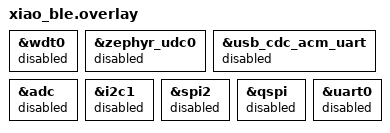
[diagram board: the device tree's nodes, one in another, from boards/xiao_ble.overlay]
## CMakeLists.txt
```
# Standalone Zephyr build for the fw1 -> fw2 (Option B) migrator.
#
# Built for the xiao_ble board to produce the unsigned base image. The ESPHome
# nrf52 build invokes this automatically (west build) during a migrator firmware
# compile, then patches the embedded fw2-bootloader blob into the result and
# signs it (see ../xiao_ble_mcuboot_migrator.py.script and README.md). No
# prebuilt binary is committed.

cmake_minimum_required(VERSION 3.20.0)

find_package(Zephyr REQUIRED HINTS $ENV{ZEPHYR_BASE})
project(xiao_ble_mcuboot_migrator LANGUAGES C)

target_sources(app PRIVATE
  src/main.c
  src/migrate.c
  src/blob.c
)

target_include_directories(app PRIVATE src)
```

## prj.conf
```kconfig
# fw1 -> fw2 (Option B) migrator -- standalone Zephyr app.
#
# This app is built ONCE, offline, into a prebuilt base binary (see README.md);
# the ESPHome build only patches the embedded fw2-bootloader blob into it. Keep
# it tiny and self-contained -- it must fit fw1's single application slot
# (0x78000) with the 48 KiB blob, and its critical section runs from RAM with
# IRQs off.

# No console/logging/printk: smaller image, no UART dependency.
CONFIG_CONSOLE=n
CONFIG_UART_CONSOLE=n
CONFIG_LOG=n
CONFIG_PRINTK=n
CONFIG_BOOT_BANNER=n
CONFIG_SERIAL=n

# CRITICAL (BOOTLOADER_UPDATER_PLAN.md 6.3): never start the watchdog. The
# nRF52 WDT cannot be stopped once running and the RAM critical section runs
# for many seconds with IRQs disabled, so it must not exist to expire.
CONFIG_WATCHDOG=n

# The critical erase/program/UICR routine executes from RAM (__ramfunc) because
# it erases the flash it was loaded from. ARCH_HAS_RAMFUNC_SUPPORT is a
# promptless symbol auto-selected by the Cortex-M arch -- it must NOT be assigned
# here (NCS Kconfig errors out when a selected/promptless symbol is assigned).

# CRC for blob integrity checking before the critical section.
CONFIG_CRC=y

# No USB stack: the migrator needs no host interaction; it runs and resets.
CONFIG_USB_DEVICE_STACK=n

# Headered for fw1's single-slot MCUboot (hash-only, signature type none -- see
# BOOTLOADER_UPDATER_PLAN.md 5). The image-signing step still needs a key file
# even though the bootloader does not verify it.
CONFIG_BOOTLOADER_MCUBOOT=y
CONFIG_MCUBOOT_SIGNATURE_KEY_FILE="root-ec-p256.pem"

# Keep the toolchain/libc minimal.
CONFIG_NFCT_PINS_AS_GPIOS=y
CONFIG_GPIO=n
CONFIG_REBOOT=y
```

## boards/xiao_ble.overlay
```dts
/*
 * Migrator board overlay (xiao_ble). Trims the device tree to the bare minimum:
 * the migrator only touches NVMC/UICR registers directly and resets. Disabling
 * the watchdog node reinforces prj.conf's CONFIG_WATCHDOG=n
 * (BOOTLOADER_UPDATER_PLAN.md 6.3 -- the WDT must never start).
 */

&wdt0 {
	status = "disabled";
};

&zephyr_udc0 {
	status = "disabled";
};

&usb_cdc_acm_uart {
	status = "disabled";
};

&adc {
	status = "disabled";
};

&i2c1 {
	status = "disabled";
};

&spi2 {
	status = "disabled";
};

&qspi {
	status = "disabled";
};

&uart0 {
	status = "disabled";
};
```

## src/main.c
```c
/*
 * fw1 -> fw2 (Option B) migrator entry point.
 *
 * Runs once, from fw1's single application slot. It validates the embedded
 * fw2-bootloader blob entirely from flash (safe: nothing is erased yet), copies
 * it into RAM, then hands off to the RAM-resident critical section that
 * actually rewrites flash and retargets UICR. See migrate.c for the dangerous
 * part and BOOTLOADER_UPDATER_PLAN.md for the design.
 *
 * Built with the watchdog disabled (BOOTLOADER_UPDATER_PLAN.md section 6.3):
 * the nRF52 WDT cannot be stopped once started, and the critical section runs
 * for many seconds with IRQs off, so it must never be fed/expired.
 */

#include <string.h>

#include <zephyr/kernel.h>
#include <zephyr/sys/crc.h>

#include "migrator.h"

/* RAM-resident copy of the blob (.bss). The critical section erases the flash
 * the original lives in, so it can only read this RAM copy. */
static struct mig_blob ram_blob;

/* Validation failed before anything was written: nothing is erased, so fw1 is
 * untouched. Stay parked (re-upload a fixed migrator over fw1 serial recovery)
 * rather than risk a half-baked migration. */
static void mig_park(void) {
  while (1) {
    k_msleep(1000);
  }
}

static int mig_blob_valid(const struct mig_blob *blob) {
  if (memcmp(blob->magic, MIG_BLOB_MAGIC, MIG_BLOB_MAGIC_LEN) != 0) {
    return 0;
  }
  if (blob->format_version != MIG_BLOB_FORMAT_VERSION) {
    return 0;
  }
  if (blob->blob_len == 0u || blob->blob_len > MIG_BLOB_CAPACITY) {
    return 0;
  }
  if (blob->target_addr != MIG_FW2_BOOTLOADER_ADDR) {
    return 0;
  }
  return crc32_ieee(blob->data, blob->blob_len) == blob->blob_crc32;
}

int main(void) {
  /* Let power/USB settle and give a human a beat to spot that the migrator
   * booted before the long, headless critical section begins. */
  k_msleep(500);

  if (!mig_blob_valid(&mig_embedded_blob)) {
    mig_park();
  }

  memcpy(&ram_blob, &mig_embedded_blob, sizeof(ram_blob));

  /* Re-validate the RAM copy: a bad memcpy/RAM fault must not reach flash. */
  if (!mig_blob_valid(&ram_blob)) {
    mig_park();
  }

  /* Hands off to RAM. Returns only on a pre-commit failure (fw1 still boots). */
  mig_run_from_ram(&ram_blob);

  mig_park();
  return 0;
}
```

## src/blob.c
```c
/*
 * Placeholder for the embedded fw2-bootloader blob.
 *
 * This object reserves space and a locatable magic marker; it carries no real
 * bootloader bytes. The ESPHome build-time injector
 * (xiao_ble_mcuboot_migrator.py.script) finds MIG_BLOB_MAGIC in the compiled
 * .bin and overwrites blob_len / blob_crc32 / target_addr / data[] with the
 * actual relocated fw2 MCUboot extracted from that build's merged.hex.
 *
 * It lives in .rodata (a non-zero initializer keeps it in the loadable image
 * rather than .bss) and is referenced by main(), so it is emitted verbatim
 * into the .bin and the injector can find it by scanning for MIG_BLOB_MAGIC.
 */

#include "migrator.h"

#ifdef __ZEPHYR__
#include <zephyr/toolchain.h>
#include <zephyr/sys/util.h>
#endif

#include <stddef.h>

/* The header must stay a fixed 32 bytes so the injector can patch by offset. */
#ifdef BUILD_ASSERT
BUILD_ASSERT(offsetof(struct mig_blob, data) == 32,
             "mig_blob header must be exactly 32 bytes");
BUILD_ASSERT(MIG_BLOB_CAPACITY >= MIG_FW2_BOOTLOADER_SIZE,
             "blob capacity too small for the fw2 bootloader region");
#endif

/* data[] must be non-zero so the whole object stays in the loadable image; the
 * 0xFF fill also matches erased flash, which the injector pads short blobs with
 * (GCC range designator -- the migrator is GCC-only under Zephyr). */
const struct mig_blob mig_embedded_blob __attribute__((used)) = {
    .magic = MIG_BLOB_MAGIC,
    .blob_len = 0u,             /* patched by the injector */
    .blob_crc32 = 0u,           /* patched by the injector */
    .target_addr = 0xFFFFFFFFu, /* patched by the injector */
    .format_version = MIG_BLOB_FORMAT_VERSION,
    .data = {[0 ... MIG_BLOB_CAPACITY - 1] = 0xFF},
};
```

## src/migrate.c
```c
/*
 * Option B critical section: program the relocated fw2 MCUboot and retarget
 * UICR.NRFFW[0], all from RAM with IRQs disabled.
 *
 * This routine erases and reprograms the very flash region the migrator was
 * loaded into (fw1's app slot starts at 0x1000, which is also the fw2
 * bootloader address), so it -- and the blob it programs -- must already live
 * in RAM before the first erase. main() copies the blob to RAM and marks this
 * code __ramfunc so Zephyr relocates it at boot.
 *
 * Ordering is chosen so fw1 stays bootable until the last possible instant:
 *   1. erase fw2 regions (BL + both slots + settings); MBR @0x0 and fw1 BL
 *      @0xF4000 are NOT in the window, so UICR.NRFFW[0] still forwards to fw1.
 *   2. program the relocated fw2 MCUboot; verify its vector table.
 *   3. on a bad vector table, just reset -- fw1 (via the untouched MBR/UICR)
 *      still comes up in serial recovery. No commit happened.
 *   4. only after the vector table checks out: ERASEUICR, then rewrite
 *      NRFFW[0]/NRFFW[1] + NFC-pins-as-GPIO + REGOUT0. This single commit flips
 *      the boot path from fw1 to fw2.
 *   5. reset into fw2 (empty primary slot -> recovery).
 *
 * See BOOTLOADER_UPDATER_PLAN.md sections 4-6 and migrator_layout.h.
 */

#include "migrator.h"

#include <nrf.h>
/*
 * Pulls in Zephyr's real __ramfunc (toolchain/gcc.h): when
 * CONFIG_ARCH_HAS_RAMFUNC_SUPPORT=y it places functions in the .ramfunc section
 * that the startup copies into RAM. Without this include, __ramfunc was
 * undefined here and the local empty fallback below left the entire critical
 * section in flash -- so the first erase wiped the page it was executing from
 * and the migration faulted partway (slot erased, UICR never committed).
 */
#include <zephyr/kernel.h>

/* NFCPINS.PROTECT cleared -> P0.09/P0.10 usable as GPIO (matches the fw2 app's
 * nfct-pins-as-gpios). After ERASEUICR the field reads 0xFFFFFFFF (NFC mode),
 * so the migrator must re-apply this. REGOUT0 (3.0V) is rewritten in the same
 * commit -- see MIG_UICR_REGOUT0_* in migrator_layout.h: the board will not run
 * fw2 at the erased 1.8V default, so it cannot be left to the fw2 app. */
#define MIG_UICR_NFCPINS_GPIO 0xFFFFFFFEu

/*
 * The critical section MUST run from RAM (it erases its own flash). Never define
 * __ramfunc to nothing as a fallback: a no-op silently produces flash-resident
 * critical code that self-erases mid-run and bricks the migration. If the arch
 * cannot relocate to RAM, fail the build loudly instead.
 */
#if !defined(CONFIG_ARCH_HAS_RAMFUNC_SUPPORT)
#error "migrator requires CONFIG_ARCH_HAS_RAMFUNC_SUPPORT: the critical erase/program section must execute from RAM"
#endif

static __ramfunc void mig_nvmc_wait(void) {
  while (NRF_NVMC->READY == NVMC_READY_READY_Busy) {
  }
}

static __ramfunc void mig_nvmc_config(uint32_t mode) {
  NRF_NVMC->CONFIG = mode;
  __DSB();
  mig_nvmc_wait();
}

static __ramfunc void mig_erase_range(uint32_t start, uint32_t end) {
  mig_nvmc_config(NVMC_CONFIG_WEN_Een);
  for (uint32_t page = start; page < end; page += MIG_FLASH_PAGE_SIZE) {
    NRF_NVMC->ERASEPAGE = page;
    __DSB();
    mig_nvmc_wait();
  }
  mig_nvmc_config(NVMC_CONFIG_WEN_Ren);
}

static __ramfunc void mig_program(uint32_t addr, const uint8_t *data, uint32_t len) {
  volatile uint32_t *dst = (volatile uint32_t *) addr;
  mig_nvmc_config(NVMC_CONFIG_WEN_Wen);
  for (uint32_t offset = 0; offset < len; offset += 4) {
    uint32_t word = 0xFFFFFFFFu;
    /* Little-endian assembly that tolerates a non-word-multiple tail. */
    uint8_t *wb = (uint8_t *) &word;
    for (uint32_t b = 0; b < 4 && (offset + b) < len; b++) {
      wb[b] = data[offset + b];
    }
    *dst = word;
    __DSB();
    mig_nvmc_wait();
    dst++;
  }
  mig_nvmc_config(NVMC_CONFIG_WEN_Ren);
}

/*
 * Reset from RAM. NVIC_SystemReset() is reached through a flash veneer
 * (____NVIC_SystemReset_veneer: `ldr pc,[pc]`) that lives in the region this
 * routine just erased -- jumping there faults. Inline the AIRCR write in a
 * __ramfunc so the reset never touches flash.
 */
static __ramfunc void mig_reset(void) {
  __DSB();
  SCB->AIRCR =
      (uint32_t) ((0x5FAUL << SCB_AIRCR_VECTKEY_Pos) | (SCB->AIRCR & SCB_AIRCR_PRIGROUP_Msk) | SCB_AIRCR_SYSRESETREQ_Msk);
  __DSB();
  for (;;) {
  }
}

static __ramfunc void mig_uicr_write(uint32_t addr, uint32_t value) {
  mig_nvmc_config(NVMC_CONFIG_WEN_Wen);
  *(volatile uint32_t *) addr = value;
  __DSB();
  mig_nvmc_wait();
  mig_nvmc_config(NVMC_CONFIG_WEN_Ren);
}

static __ramfunc void mig_uicr_erase(void) {
  mig_nvmc_config(NVMC_CONFIG_WEN_Een);
  NRF_NVMC->ERASEUICR = NVMC_ERASEUICR_ERASEUICR_Erase;
  __DSB();
  mig_nvmc_wait();
  mig_nvmc_config(NVMC_CONFIG_WEN_Ren);
}

/* A valid Cortex-M vector table starts with the initial stack pointer (must
 * point into RAM) followed by the reset vector (a thumb address in flash). */
static __ramfunc int mig_vector_table_ok(uint32_t addr) {
  const uint32_t *vt = (const uint32_t *) addr;
  uint32_t sp = vt[0];
  uint32_t reset = vt[1];
  if (sp < MIG_RAM_START || sp > MIG_RAM_END) {
    return 0;
  }
  if ((reset & 1u) == 0u) { /* reset vector must be a thumb (odd) address */
    return 0;
  }
  if (reset < MIG_ERASE_START || reset >= MIG_FLASH_END) {
    return 0;
  }
  return 1;
}

void __ramfunc mig_run_from_ram(const struct mig_blob *blob) {
  __disable_irq();

  /* Disable the ARM MPU and the NVMC instruction cache before touching flash.
   * Programming nRF flash is a CPU store straight to the flash address; if the
   * MPU's code-region attributes forbid that store in our context it faults, and
   * because we run from RAM with our own vector table about to be erased, that
   * fault escalates to an unrecoverable lockup. Disabling the MPU here keeps the
   * direct flash stores legal; clearing ICACHE keeps post-write readbacks
   * (mig_vector_table_ok) coherent with what we just programmed. Both are safe:
   * IRQs are off and we execute entirely from RAM. */
  MPU->CTRL = 0u;
  __DSB();
  __ISB();
  NRF_NVMC->ICACHECNF = 0u;
  __DSB();

  /* 1. Erase the relocated fw2 bootloader + both fw2 slots. The window stops
   *    below fw1's MCUboot @0xF4000 (see MIG_ERASE_END), so until the UICR
   *    commit below fw1 stays the bootable fallback via the untouched MBR. */
  mig_erase_range(MIG_ERASE_START, MIG_ERASE_END);

  /* 2. Program the relocated fw2 MCUboot from the RAM-resident blob. */
  mig_program(blob->target_addr, blob->data, blob->blob_len);

  /* 3. Pre-commit safety gate: if the new bootloader's vector table is bad,
   *    do NOT touch UICR -- reset back into the still-bootable fw1. */
  if (!mig_vector_table_ok(blob->target_addr)) {
    mig_reset(); /* fw1 (untouched MBR/UICR/BL) still comes up in serial recovery */
  }

  /* 4. Commit the boot path: ERASEUICR wipes all of UICR, so every word fw2
   *    needs must be rewritten here (NRFFW[0/1] + NFC-pins-as-GPIO + REGOUT0).
   *    REGOUT0 is critical: without it the board boots fw2 at 1.8V and hangs. */
  mig_uicr_erase();
  mig_uicr_write(MIG_UICR_NRFFW0_ADDR, MIG_UICR_NRFFW0_VALUE);
  mig_uicr_write(MIG_UICR_NRFFW1_ADDR, MIG_UICR_NRFFW1_VALUE);
  mig_uicr_write((uint32_t) &NRF_UICR->NFCPINS, MIG_UICR_NFCPINS_GPIO);
  mig_uicr_write(MIG_UICR_REGOUT0_ADDR, MIG_UICR_REGOUT0_VALUE);

  /* 5. Reset into fw2. */
  mig_reset();
}
```

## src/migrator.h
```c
/*
 * Shared declarations for the fw1 -> fw2 (Option B) migrator app.
 *
 * The embedded fw2-bootloader blob is described by mig_blob, a fixed-layout
 * structure the build-time injector (xiao_ble_mcuboot_migrator.py.script)
 * patches in place: it finds the 16-byte magic, then overwrites blob_len,
 * blob_crc32, target_addr and the data[] payload. Keeping the layout fixed and
 * little-endian lets the injector work on the raw .bin without an ELF parser.
 */

#ifndef ESPHOME_NRF52_MIGRATOR_H
#define ESPHOME_NRF52_MIGRATOR_H

#include <stdint.h>
#include "../migrator_layout.h"

/* Bumped if the on-flash blob contract changes; the injector writes the same. */
#define MIG_BLOB_FORMAT_VERSION 1u

/*
 * Fixed 32-byte header followed by the payload. The injector and migrate.c must
 * agree byte-for-byte, so the layout is asserted at compile time in blob.c.
 */
struct mig_blob {
  uint8_t magic[MIG_BLOB_MAGIC_LEN]; /* MIG_BLOB_MAGIC, no trailing NUL */
  uint32_t blob_len;                 /* fw2 bootloader byte count (<= capacity) */
  uint32_t blob_crc32;               /* crc32_ieee over data[0 .. blob_len) */
  uint32_t target_addr;              /* program destination (== fw2 BL addr) */
  uint32_t format_version;           /* MIG_BLOB_FORMAT_VERSION */
  uint8_t data[MIG_BLOB_CAPACITY];   /* fw2 bootloader bytes, 0xFF-padded */
};

/* The single embedded blob instance (src/blob.c). */
extern const struct mig_blob mig_embedded_blob;

/*
 * The RAM-resident critical section. Runs with IRQs disabled from RAM because
 * it erases and reprograms the flash region the migrator itself was loaded
 * into. Never returns on success (it resets); returns only on a pre-commit
 * sanity failure, after which fw1 (via the untouched MBR) is still bootable.
 */
void mig_run_from_ram(const struct mig_blob *blob);

#endif /* ESPHOME_NRF52_MIGRATOR_H */
```
